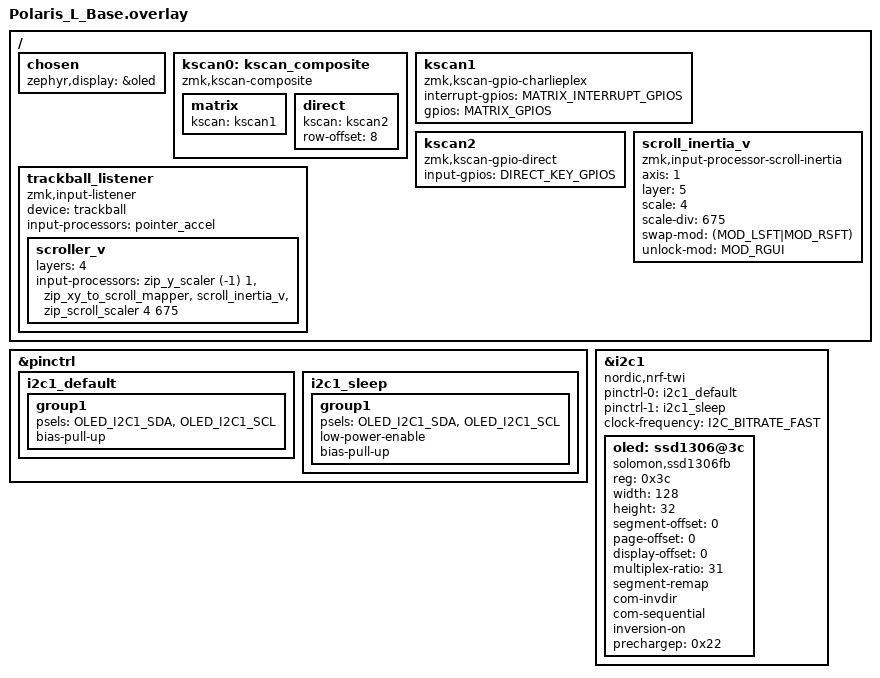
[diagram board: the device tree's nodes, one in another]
#include "Polaris.dtsi"
#include "Polaris_L_interior.dtsi"
#include <input/processors/runtime-input-processor.dtsi>
#include <input/processors.dtsi>
#include <dt-bindings/zmk/modifiers.h>
#include <dt-bindings/zmk/pointing.h>

/ {
    chosen {
        zephyr,display = &oled;
    };

    kscan0: kscan_composite {
        compatible = "zmk,kscan-composite";
        matrix {
            kscan = <&kscan1>;
        };
        direct {
            kscan = <&kscan2>;
            row-offset = <8>;
        };
    };

    kscan1: kscan1 {
        compatible = "zmk,kscan-gpio-charlieplex";
        interrupt-gpios = MATRIX_INTERRUPT_GPIOS;
        gpios
            = MATRIX_GPIOS
            ;
    };
    
    kscan2: kscan2 {
        compatible = "zmk,kscan-gpio-direct";
        input-gpios
            = DIRECT_KEY_GPIOS
            ;
    };

    scroll_inertia_v: scroll_inertia_v {
        compatible = "zmk,input-processor-scroll-inertia";
        #input-processor-cells = <0>;

        /* axis: 0 = 両軸（自由2D）,
                  1 = Y軸のみ（縦スクロール）,
                  2 = X軸のみ（横スクロール） */
        axis      = <1>;
        layer     = <5>;          /* 縦スクロール用のレイヤー番号 */

        /* 後段の zip_scroll_scaler の引数と合わせる */
        scale     = <4>;
        scale-div = <675>;

        /* オプション: Shiftを押している間だけ出力軸を反転 */
        swap-mod  = <(MOD_LSFT|MOD_RSFT)>;

        /* オプション: 右GUIを押している間だけ両軸フリー （2Dスクロール） */
        unlock-mod = <MOD_RGUI>;
    };

     trackball_listener: trackball_listener {
        compatible = "zmk,input-listener";
        device = <&trackball>;
        input-processors = <&pointer_accel /* など */>;

        scroller_v {
            layers = <5>;
            input-processors = <
                &zip_y_scaler (-1) 1
                &zip_xy_to_scroll_mapper
                &scroll_inertia_v
                &zip_scroll_scaler 4 675
            >;
        };
};
};

&pinctrl {    
    i2c1_default: i2c1_default {
        group1 {
            psels = <OLED_I2C1_SDA>,
                    <OLED_I2C1_SCL>;
            bias-pull-up;
        };
    };
      
    i2c1_sleep: i2c1_sleep {
        group1 {
            psels = <OLED_I2C1_SDA>,
                    <OLED_I2C1_SCL>;
            low-power-enable;
            bias-pull-up;
        };
    };
};

&i2c1 {
    status = "okay";
    compatible = "nordic,nrf-twi";
    pinctrl-0 = <&i2c1_default>;
    pinctrl-1 = <&i2c1_sleep>;
    pinctrl-names = "default", "sleep";
    clock-frequency = <I2C_BITRATE_FAST>; 
    
    oled: ssd1306@3c {
        compatible = "solomon,ssd1306fb";
        reg = <0x3c>;
        width = <128>;
        height = <32>;
        segment-offset = <0>;
        page-offset = <0>;
        display-offset = <0>;
        multiplex-ratio = <31>;
        segment-remap;
        com-invdir;
        com-sequential;
        inversion-on;
        prechargep = <0x22>;
    };
};

&trackball_listener {
    scroller_v {
        layers = <4>;
        input-processors = <
            &zip_y_scaler (-1) 1
            &zip_xy_to_scroll_mapper
            &scroll_inertia_v
            &zip_scroll_scaler 4 675
        >;
    };
};
